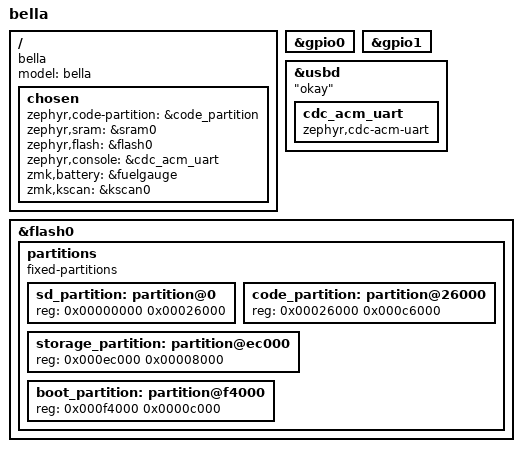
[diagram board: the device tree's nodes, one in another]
/*
 * Copyright (c) 2023 The ZMK Contributors
 *
 * SPDX-License-Identifier: MIT
 */

/dts-v1/;
#include <nordic/nrf52840_qiaa.dtsi>
#include <dt-bindings/zmk/matrix_transform.h>

#include "bella-transforms.dtsi"
#include "bella-layouts.dtsi"


/ {
    model = "bella";
    compatible = "bella";

    chosen {
        zephyr,code-partition = &code_partition;
        zephyr,sram = &sram0;
        zephyr,flash = &flash0;
        zephyr,console = &cdc_acm_uart;
        zmk,battery = &fuelgauge;
        zmk,kscan = &kscan0;
    };
};

&gpio0 {
    status = "okay";
};

&gpio1 {
    status = "okay";
};

&usbd {
    status = "okay";
    cdc_acm_uart: cdc_acm_uart {
        compatible = "zephyr,cdc-acm-uart";
    };
};

zephyr_udc0: &usbd {
  status: "okay";
  cdc_acm_uart: cdc_acm_uart {
  compatible = "zephyr,cdc-acm-uart";
  };
};

&flash0 {
    partitions {
        compatible = "fixed-partitions";
        #address-cells = <1>;
        #size-cells = <1>;

        sd_partition: partition@0 {
            reg = <0x00000000 0x00026000>;
        };
        code_partition: partition@26000 {
            reg = <0x00026000 0x000c6000>;
        };

        /*
         * The flash starting at 0x000ec000 and ending at
         * 0x000f3fff is reserved for use by the application.
         */

        /*
         * Storage partition will be used by FCB/LittleFS/NVS
         * if enabled.
         */
        storage_partition: partition@ec000 {
            reg = <0x000ec000 0x00008000>;
        };

        boot_partition: partition@f4000 {
            reg = <0x000f4000 0x0000c000>;
        };
    };
};
